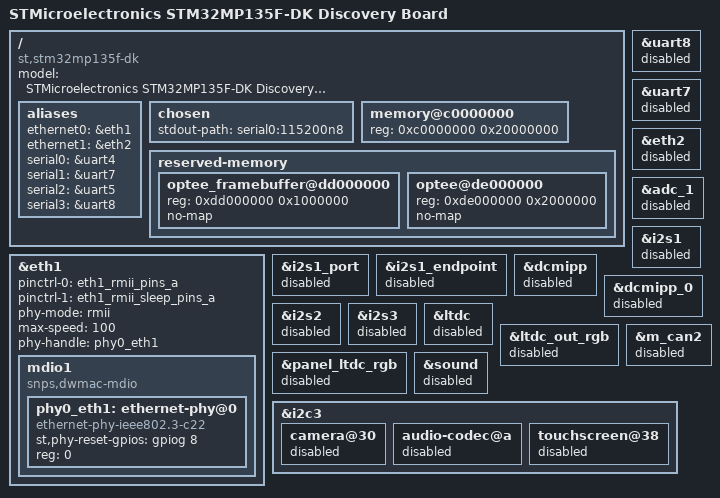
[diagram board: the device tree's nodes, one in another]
// SPDX-License-Identifier: (GPL-2.0+ OR BSD-3-Clause)
/*
 * Copyright (C) MYiR 2022 - All Rights Reserved
 * Author: Alexhu <fan.hu@myirtech.com> for MYiR.
 */

/dts-v1/;

#include "myb-stm32mp135x-base.dtsi"

/ {
	model = "STMicroelectronics STM32MP135F-DK Discovery Board";
	compatible = "st,stm32mp135f-dk", "st,stm32mp135";

	aliases {
		ethernet0 = &eth1;
		ethernet1 = &eth2;
		serial0 = &uart4;
		serial1 = &uart7;
		serial2 = &uart5;
		serial3 = &uart8;
	};

	chosen {
		#address-cells = <1>;
		#size-cells = <1>;
		ranges;
		stdout-path = "serial0:115200n8";
	};

	memory@c0000000 {
		device_type = "memory";
		reg = <0xc0000000 0x20000000>;
	};

	reserved-memory {
		#address-cells = <1>;
		#size-cells = <1>;
		ranges;

		optee_framebuffer@dd000000 {
			reg = <0xdd000000 0x1000000>;
			no-map;
		};

		optee@de000000 {
			reg = <0xde000000 0x2000000>;
			no-map;
		};
	};
};

&eth1 {
	status = "okay";
	pinctrl-0 = <&eth1_rmii_pins_a>;
	pinctrl-1 = <&eth1_rmii_sleep_pins_a>;
	pinctrl-names = "default", "sleep";
	phy-mode = "rmii";
	max-speed = <100>;
	phy-handle = <&phy0_eth1>;
	// st,ext-phyclk;
	// st,eth-clk-sel = <1>;
	
	mdio1 {
		#address-cells = <1>;
		#size-cells = <0>;
		compatible = "snps,dwmac-mdio";
		phy0_eth1: ethernet-phy@0 {
			st,phy-reset-gpios = <&gpiog 8 GPIO_ACTIVE_HIGH>;
			compatible = "ethernet-phy-ieee802.3-c22", "ethernet-phy-id0007.c0f1", "ethernet-phy-id001c.c912";
			reg = <0>;
		};
	};
};

// disable uart8
&uart8 {
	status = "disabled";
};

// disable uart4
// &uart4 {
// 	status = "disabled";
// };

// disable uart7
&uart7 {
	status = "disabled";
};

&eth2 {
	status = "disabled";
};

// disable adc_1 to free up DMA channels
&adc_1 {
	status = "disabled";
};

// disable i2s1 to reclaim PA6
&i2s1 {
	status = "disabled";
};

&i2s1_port {
	status = "disabled";
};

&i2s1_endpoint {
	status = "disabled";
};

// disable dcmipp to reclaim PB8
&dcmipp {
	status = "disabled";
};

&dcmipp_0 {
	status = "disabled";
};

// disable i2s* (duplicate unit-address)
&i2s2 {
	status = "disabled";
};

&i2s3 {
	status = "disabled";
};

// disable LCD
&ltdc {
	status = "disabled";
};

&ltdc_out_rgb {
	status = "disabled";
};

&panel_ltdc_rgb {
	status = "disabled";
};

// disable CAN2
&m_can2 {
	status = "disabled";
};

// disable audio
&sound {
	status = "disabled";
};

// disable unused i2c3 devices
&i2c3 {
	camera@30 {
		status = "disabled";
	};

	audio-codec@a {
		status = "disabled";
	};

	touchscreen@38 {
		status = "disabled";
	};
};

